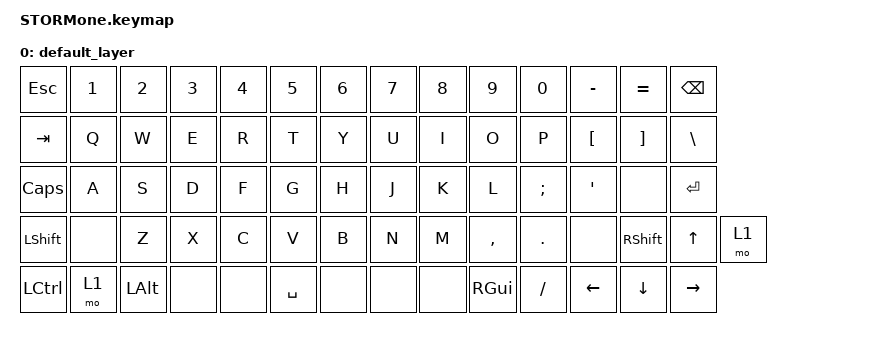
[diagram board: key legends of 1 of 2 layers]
#include <behaviors.dtsi>
#include <dt-bindings/zmk/keys.h>
#include <dt-bindings/zmk/bt.h>

/ {
    keymap {
            compatible = "zmk,keymap";

            default_layer {
            bindings = <
&kp ESC    &kp N1   &kp N2   &kp N3 &kp N4 &kp N5    &kp N6 &kp N7 &kp N8 &kp N9    &kp N0     &kp MINUS &kp EQUAL  &kp BSPC
&kp TAB    &kp Q    &kp W    &kp E  &kp R  &kp T     &kp Y  &kp U  &kp I  &kp O     &kp P      &kp LBKT  &kp RBKT   &kp BSLH
&kp CAPS   &kp A    &kp S    &kp D  &kp F  &kp G     &kp H  &kp J  &kp K  &kp L     &kp SEMI   &kp APOS  &none      &kp ENTER
&kp LSHIFT &none    &kp Z    &kp X  &kp C  &kp V     &kp B  &kp N  &kp M  &kp COMMA &kp PERIOD &none     &kp RSHIFT &kp UP     &mo 1
&kp LCTRL  &mo 1 &kp LALT &none  &none  &kp SPACE &none  &none  &none  &kp RGUI  &kp SLASH     &kp LEFT   &kp DOWN   &kp RIGHT
                >;
            };
            lower_layer {
            bindings = <
&kp GRAVE  &kp F1       &kp F2       &kp F3       &kp F4       &kp F5       &kp F6 &kp F7 &kp F8 &kp F9 &kp F10 &kp F11 &kp F12 &kp DEL
&kp TILDE &bt BT_CLR &bt BT_SEL 0 &bt BT_SEL 1 &bt BT_SEL 2 &bt BT_SEL 3 &bt BT_SEL 4
                >;
        };
    };
};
